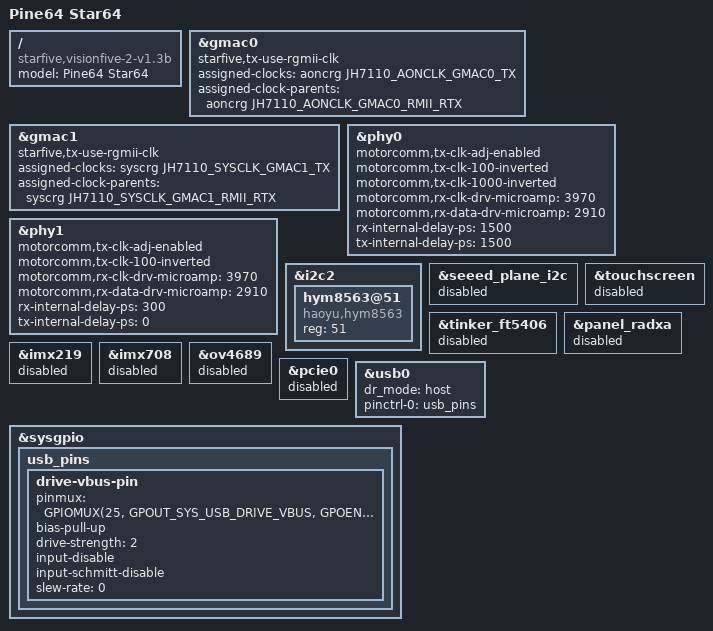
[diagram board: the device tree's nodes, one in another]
// SPDX-License-Identifier: GPL-2.0 OR MIT
/*
 * Copyright (C) 2022 StarFive Technology Co., Ltd.
 * Copyright (C) 2022 Emil Renner Berthing <kernel@esmil.dk>
 */

/dts-v1/;
#include "jh7110-starfive-visionfive-2.dtsi"

/ {
	model = "Pine64 Star64";
	compatible = "starfive,visionfive-2-v1.3b", "starfive,jh7110", "pine64,star64";
};

&gmac0 {
	starfive,tx-use-rgmii-clk;
	assigned-clocks = <&aoncrg JH7110_AONCLK_GMAC0_TX>;
	assigned-clock-parents = <&aoncrg JH7110_AONCLK_GMAC0_RMII_RTX>;
};

&gmac1 {
	starfive,tx-use-rgmii-clk;
	assigned-clocks = <&syscrg JH7110_SYSCLK_GMAC1_TX>;
	assigned-clock-parents = <&syscrg JH7110_SYSCLK_GMAC1_RMII_RTX>;
};

&phy0 {
	motorcomm,tx-clk-adj-enabled;
	motorcomm,tx-clk-100-inverted;
	motorcomm,tx-clk-1000-inverted;
	motorcomm,rx-clk-drv-microamp = <3970>;
	motorcomm,rx-data-drv-microamp = <2910>;
	rx-internal-delay-ps = <1500>;
	tx-internal-delay-ps = <1500>;
};

&phy1 {
	motorcomm,tx-clk-adj-enabled;
	motorcomm,tx-clk-100-inverted;
	motorcomm,rx-clk-drv-microamp = <3970>;
	motorcomm,rx-data-drv-microamp = <2910>;
	rx-internal-delay-ps = <300>;
	tx-internal-delay-ps = <0>;
};

&i2c2 {
	hym8563@51 {
		compatible = "haoyu,hym8563";
		reg = <51>;
	};
};

&seeed_plane_i2c {
	status = "disabled";
};

&tinker_ft5406 {
	status = "disabled";
};

&touchscreen {
	status = "disabled";
};

&panel_radxa {
	status = "disabled";
};

&imx219 {
	status = "disabled";
};

&imx708 {
	status = "disabled";
};

&ov4689 {
	status = "disabled";
};

&pcie0 {
	status = "disabled";
};

&usb0 {
	dr_mode = "host";
	status = "okay";
	pinctrl-names = "default";
	pinctrl-0 = <&usb_pins>;
};

&sysgpio {
	usb_pins: usb_pins {
		drive-vbus-pin {
			pinmux = <GPIOMUX(25, GPOUT_SYS_USB_DRIVE_VBUS,
						GPOEN_DISABLE, GPI_NONE)>;
			bias-pull-up;
			drive-strength = <2>;
			input-disable;
			input-schmitt-disable;
			slew-rate = <0>;
		};
	};
};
